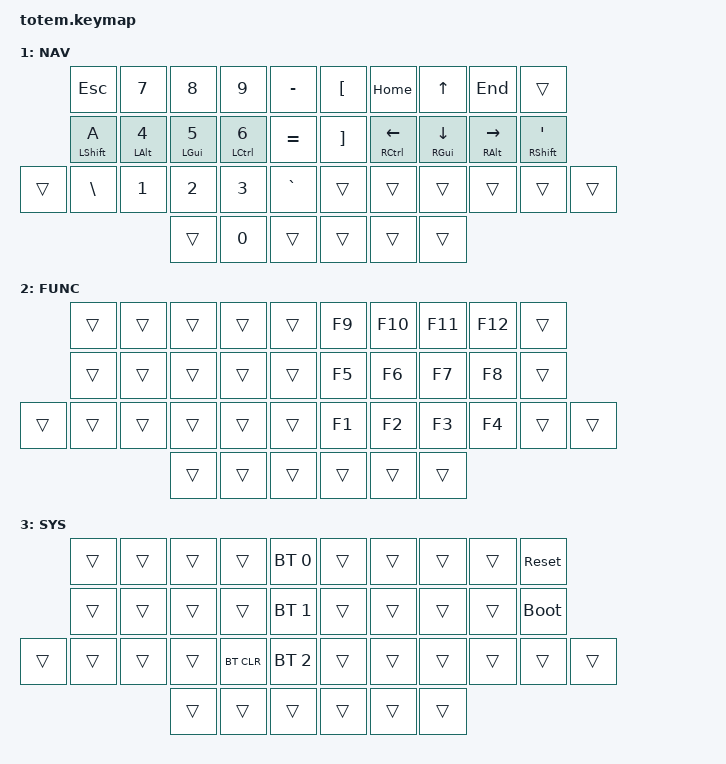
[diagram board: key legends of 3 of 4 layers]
//
//                                                        ▀▀▀▀▀     ▀▀▀▀▀          ▀▀█▀▀
//                                                        ▄▀▀▀▄  ▄  ▄▀▀▀▄  ▄  ▄▀▀▀▄  █  ▄▀▀▀▄
//                                                        █   █  █  █   █  █  █   █  █  █   █
//                                                         ▀▀▀   █   ▀▀▀   █   ▀▀▀   ▀   ▀▀▀
//                                                               █      ▄▄▄█▄▄▄    █   █  
//                                                               ▀      █  █  █     █▄█
//                                                             ▀▀▀▀▀    █  █  █      ▀
//                                                                      ▀  ▀  ▀
//
// ▄▄▄▄▄▄▄▄▄▄▄▄▄▄▄▄▄▄▄▄▄▄▄▄▄▄▄▄▄▄▄▄▄▄▄▄▄▄▄▄▄▄▄▄▄▄▄▄▄▄▄▄▄▄▄▄▄▄▄▄▄▄▄▄▄▄▄▄▄▄▄▄▄▄▄▄▄▄▄▄▄▄▄▄▄▄▄▄▄▄▄▄▄▄▄▄▄▄▄▄▄▄▄▄▄▄▄▄▄▄▄▄▄▄▄▄▄▄▄▄▄▄▄▄▄▄▄▄▄▄▄▄▄▄▄▄▄▄▄▄▄▄▄▄▄▄▄▄▄
       

#include <behaviors.dtsi>
#include <dt-bindings/zmk/keys.h>
#include <dt-bindings/zmk/bt.h>
#include <dt-bindings/zmk/outputs.h>

#define BASE 0
#define NAV  1
#define FUNC  2
#define SYS  3

// Home row mods macro
#define HRML(k1,k2,k3,k4) &ht LSHFT k1  &ht LALT k2  &ht LGUI k3  &ht LCTRL k4
#define HRMR(k1,k2,k3,k4) &ht LCTRL k1  &ht RGUI k2  &ht RALT k3  &ht RSHFT k4

/ {
    behaviors {
        td0: tap_dance_0 {
            compatible = "zmk,behavior-tap-dance";
            #binding-cells = <0>;
            tapping-term-ms = <200>;
            bindings = <&kp LG(C)>, <&kp LG(V)>, <&kp LG(X)>;
        };
        ht: hold_tap {
            compatible = "zmk,behavior-hold-tap";
            #binding-cells = <2>;
            flavor = "tap-preferred";
            tapping-term-ms = <200>;
            quick-tap-ms = <150>;
            require-prior-idle-ms = <100>;
            bindings = <&kp>, <&kp>;
        };
    };

     combos {
        compatible = "zmk,combos";
        combo_ralt {
            timeout-ms = <50>;
            key-positions = <16 17>;
            bindings = <&kp RALT>;
        };
        combo_caps {
            timeout-ms = <50>;
            key-positions = <12 13>;
            bindings = <&kp CAPS>;
        };
        combo_shift_q {
            timeout-ms = <35>;
            key-positions = <0 10>;
            bindings = <&kp LS(Q)>;
        };
        combo_shift_w {
            timeout-ms = <35>;
            key-positions = <1 10>;
            bindings = <&kp LS(W)>;
        };
        combo_shift_e {
            timeout-ms = <35>;
            key-positions = <2 10>;
            bindings = <&kp LS(E)>;
        };
        combo_shift_r {
            timeout-ms = <35>;
            key-positions = <3 10>;
            bindings = <&kp LS(R)>;
        };
        combo_shift_t {
            timeout-ms = <35>;
            key-positions = <4 10>;
            bindings = <&kp LS(T)>;
        };
        combo_shift_o {
            timeout-ms = <35>;
            key-positions = <8 19>;
            bindings = <&kp LS(O)>;
        };
        combo_shift_p {
            timeout-ms = <35>;
            key-positions = <9 19>;
            bindings = <&kp LS(P)>;
        };
    };

    conditional_layers {
        compatible = "zmk,conditional-layers";
        tri_layer {
            if-layers = <1 2>;
            then-layer = <3>;
        };
    };

    macros {
        langhold: langhold {
            compatible = "zmk,behavior-macro";
            label = "ZM_langhold";
            #binding-cells = <0>;
            bindings
            = <&macro_press &kp CAPS>
            , <&macro_pause_for_release>
            , <&macro_release &kp CAPS>
            ;
        };
    };

        keymap {
                compatible = "zmk,keymap";
// ▄▄▄▄▄▄▄▄▄▄▄▄▄▄▄▄▄▄▄▄▄▄▄▄▄▄▄▄▄▄▄▄▄▄▄▄▄▄▄▄▄▄▄▄▄▄▄▄▄▄▄▄▄▄▄▄▄▄▄▄▄▄▄▄▄▄▄▄▄▄▄▄▄▄▄▄▄▄▄▄▄▄▄▄▄▄▄▄▄▄▄▄▄▄▄▄▄▄▄▄▄▄▄▄▄▄▄▄▄▄▄▄▄▄▄▄▄▄▄▄▄▄▄▄▄▄▄▄▄▄▄▄▄▄▄▄▄▄▄▄▄▄▄▄▄▄▄▄▄

                base_layer {
// ┏━━━━━━━━━━━━━━━━━━━━━━━━━━━━━━━━━━━━━━━┓
label= "BASE"                              ;
// ┗━━━━━━━━━━━━━━━━━━━━━━━━━━━━━━━━━━━━━━━┛
//             ┏━━━━━━━━━━━┳━━━━━━━━━━━┳━━━━━━━━━━━┳━━━━━━━━━━━┳━━━━━━━━━━━┓   ┏━━━━━━━━━━━┳━━━━━━━━━━━┳━━━━━━━━━━━┳━━━━━━━━━━━┳━━━━━━━━━━━┓
//             ┃     Q     ┃     W     ┃     E     ┃     R     ┃     T     ┃   ┃     Y     ┃     U     ┃     I     ┃     O     ┃     P     ┃
//             ┣━━━━━━━━━━━╋━━━━━━━━━━━╋━━━━━━━━━━━╋━━━━━━━━━━━╋━━━━━━━━━━━┫   ┣━━━━━━━━━━━╋━━━━━━━━━━━╋━━━━━━━━━━━╋━━━━━━━━━━━╋━━━━━━━━━━━┫
//             ┃     A     ┃     S     ┃     D     ┃     F     ┃     G     ┃   ┃     H     ┃     J     ┃     K     ┃     L     ┃     ;     ┃
// ┏━━━━━━━━━━━╋━━━━━━━━━━━╋━━━━━━━━━━━╋━━━━━━━━━━━╋━━━━━━━━━━━╋━━━━━━━━━━━┫   ┣━━━━━━━━━━━╋━━━━━━━━━━━╋━━━━━━━━━━━╋━━━━━━━━━━━╋━━━━━━━━━━━╋━━━━━━━━━━━┓
// ┃    td0    ┃     Z     ┃     X     ┃     C     ┃     V     ┃     B     ┃   ┃     N     ┃     M     ┃     ,     ┃     .     ┃     /     ┃     \     ┃
// ┗━━━━━━━━━━━┻━━━━━━━━━━━┻━━━━━━━━━━━╋━━━━━━━━━━━╋━━━━━━━━━━━╋━━━━━━━━━━━┫   ┣━━━━━━━━━━━╋━━━━━━━━━━━╋━━━━━━━━━━━╋━━━━━━━━━━━┻━━━━━━━━━━━┻━━━━━━━━━━━┛
//                                     ┃    ESC    ┃    TAB    ┃    SPC    ┃   ┃   ENTER   ┃  BSPC     ┃   DEL     ┃
//                                     ┗━━━━━━━━━━━┻━━━━━━━━━━━┻━━━━━━━━━━━┛   ┗━━━━━━━━━━━┻━━━━━━━━━━━┻━━━━━━━━━━━┛
 bindings = <
// ╷           ╷           ╷           ╷           ╷           ╷           ╷   ╷           ╷           ╷           ╷           ╷           ╷           ╷

                &kp Q       &kp W       &kp E       &kp R       &kp T           &kp Y       &kp U       &kp I       &kp O       &kp P
                HRML(A,     S,          D,          F)          &kp G           &kp H       HRMR(J,     K,          L,          SEMI)
    &td0        &kp Z       &kp X       &kp C       &kp V       &kp B           &kp N       &kp M       &kp COMMA   &kp DOT     &kp FSLH    &langhold
                                        &kp ESC     &kp TAB     &lt 1 SPACE     &lt 1 ENTER &lt 2 BSPC  &kp DEL
                        >;
                };

// ▄▄▄▄▄▄▄▄▄▄▄▄▄▄▄▄▄▄▄▄▄▄▄▄▄▄▄▄▄▄▄▄▄▄▄▄▄▄▄▄▄▄▄▄▄▄▄▄▄▄▄▄▄▄▄▄▄▄▄▄▄▄▄▄▄▄▄▄▄▄▄▄▄▄▄▄▄▄▄▄▄▄▄▄▄▄▄▄▄▄▄▄▄▄▄▄▄▄▄▄▄▄▄▄▄▄▄▄▄▄▄▄▄▄▄▄▄▄▄▄▄▄▄▄▄▄▄▄▄▄▄▄▄▄▄▄▄▄▄▄▄▄▄▄▄▄▄▄▄


                nav_layer {
// ┏━━━━━━━━━━━━━━━━━━━━━━━━━━━━━━━━━━━━━━━┓
label= "NAV"                              ;
// ┗━━━━━━━━━━━━━━━━━━━━━━━━━━━━━━━━━━━━━━━┛
//             ┏━━━━━━━━━━━┳━━━━━━━━━━━┳━━━━━━━━━━━┳━━━━━━━━━━━┳━━━━━━━━━━━┓   ┏━━━━━━━━━━━┳━━━━━━━━━━━┳━━━━━━━━━━━┳━━━━━━━━━━━┳━━━━━━━━━━━┓
//             ┃    ESC    ┃     7     ┃     8     ┃     9     ┃     -     ┃   ┃     [     ┃   HOME    ┃    UP     ┃    END    ┃           ┃
//             ┣━━━━━━━━━━━╋━━━━━━━━━━━╋━━━━━━━━━━━╋━━━━━━━━━━━╋━━━━━━━━━━━┫   ┣━━━━━━━━━━━╋━━━━━━━━━━━╋━━━━━━━━━━━╋━━━━━━━━━━━╋━━━━━━━━━━━┫
//             ┃           ┃     4     ┃     5     ┃     6     ┃     =     ┃   ┃     ]     ┃   LEFT    ┃   DOWN    ┃   RIGHT   ┃     '     ┃
// ┏━━━━━━━━━━━╋━━━━━━━━━━━╋━━━━━━━━━━━╋━━━━━━━━━━━╋━━━━━━━━━━━╋━━━━━━━━━━━┫   ┣━━━━━━━━━━━╋━━━━━━━━━━━╋━━━━━━━━━━━╋━━━━━━━━━━━╋━━━━━━━━━━━╋━━━━━━━━━━━┓
// ┃           ┃    BSLH   ┃     1     ┃     2     ┃     3     ┃     ~     ┃   ┃           ┃           ┃           ┃           ┃           ┃           ┃
// ┗━━━━━━━━━━━┻━━━━━━━━━━━┻━━━━━━━━━━━╋━━━━━━━━━━━╋━━━━━━━━━━━╋━━━━━━━━━━━┫   ┣━━━━━━━━━━━╋━━━━━━━━━━━╋━━━━━━━━━━━╋━━━━━━━━━━━┻━━━━━━━━━━━┻━━━━━━━━━━━┛
//                                     ┃           ┃     0     ┃           ┃   ┃           ┃           ┃           ┃
//                                     ┗━━━━━━━━━━━┻━━━━━━━━━━━┻━━━━━━━━━━━┛   ┗━━━━━━━━━━━┻━━━━━━━━━━━┻━━━━━━━━━━━┛
 bindings = <
// ╷           ╷           ╷           ╷           ╷           ╷           ╷   ╷           ╷           ╷           ╷           ╷           ╷           ╷

                &kp ESC     &kp N7      &kp N8      &kp N9       &kp MINUS       &kp LBKT  &kp HOME       &kp UP        &kp END        &trans
                &mt LSHFT A &mt LALT N4 &mt LGUI N5 &mt LCTRL N6 &kp EQUAL       &kp RBKT  &mt RCTRL LEFT &mt RGUI DOWN &mt RALT RIGHT &mt RSHFT SQT
    &trans      &kp BSLH    &kp N1      &kp N2      &kp N3       &kp GRAVE       &trans    &trans         &trans        &trans         &trans       &trans
                                        &trans      &kp N0       &trans          &trans    &trans         &trans      
                        >;
                };

// ▄▄▄▄▄▄▄▄▄▄▄▄▄▄▄▄▄▄▄▄▄▄▄▄▄▄▄▄▄▄▄▄▄▄▄▄▄▄▄▄▄▄▄▄▄▄▄▄▄▄▄▄▄▄▄▄▄▄▄▄▄▄▄▄▄▄▄▄▄▄▄▄▄▄▄▄▄▄▄▄▄▄▄▄▄▄▄▄▄▄▄▄▄▄▄▄▄▄▄▄▄▄▄▄▄▄▄▄▄▄▄▄▄▄▄▄▄▄▄▄▄▄▄▄▄▄▄▄▄▄▄▄▄▄▄▄▄▄▄▄▄▄▄▄▄▄▄▄▄


                func_layer {
// ┏━━━━━━━━━━━━━━━━━━━━━━━━━━━━━━━━━━━━━━━┓
label= "FUNC"                               ;
// ┗━━━━━━━━━━━━━━━━━━━━━━━━━━━━━━━━━━━━━━━┛
//             ┏━━━━━━━━━━━┳━━━━━━━━━━━┳━━━━━━━━━━━┳━━━━━━━━━━━┳━━━━━━━━━━━┓   ┏━━━━━━━━━━━┳━━━━━━━━━━━┳━━━━━━━━━━━┳━━━━━━━━━━━┳━━━━━━━━━━━┓
//             ┃           ┃           ┃           ┃           ┃           ┃   ┃   F9      ┃   F10     ┃   F11     ┃   F12     ┃           ┃
//             ┣━━━━━━━━━━━╋━━━━━━━━━━━╋━━━━━━━━━━━╋━━━━━━━━━━━╋━━━━━━━━━━━┫   ┣━━━━━━━━━━━╋━━━━━━━━━━━╋━━━━━━━━━━━╋━━━━━━━━━━━╋━━━━━━━━━━━┫
//             ┃           ┃           ┃           ┃           ┃           ┃   ┃   F5      ┃   F6      ┃   F7      ┃   F8      ┃           ┃
// ┏━━━━━━━━━━━╋━━━━━━━━━━━╋━━━━━━━━━━━╋━━━━━━━━━━━╋━━━━━━━━━━━╋━━━━━━━━━━━┫   ┣━━━━━━━━━━━╋━━━━━━━━━━━╋━━━━━━━━━━━╋━━━━━━━━━━━╋━━━━━━━━━━━╋━━━━━━━━━━━┓
// ┃           ┃           ┃           ┃           ┃           ┃           ┃   ┃   F1      ┃   F2      ┃   F3      ┃   F4      ┃           ┃           ┃
// ┗━━━━━━━━━━━┻━━━━━━━━━━━┻━━━━━━━━━━━╋━━━━━━━━━━━╋━━━━━━━━━━━╋━━━━━━━━━━━┫   ┣━━━━━━━━━━━╋━━━━━━━━━━━╋━━━━━━━━━━━╋━━━━━━━━━━━┻━━━━━━━━━━━┻━━━━━━━━━━━┛
//                                     ┃           ┃           ┃           ┃   ┃           ┃           ┃           ┃
//                                     ┗━━━━━━━━━━━┻━━━━━━━━━━━┻━━━━━━━━━━━┛   ┗━━━━━━━━━━━┻━━━━━━━━━━━┻━━━━━━━━━━━┛
 bindings = <
// ╷           ╷           ╷           ╷           ╷           ╷           ╷   ╷           ╷           ╷           ╷           ╷           ╷           ╷

                &trans     &trans       &trans       &trans      &trans         &kp F9      &kp F10     &kp F11      &kp F12     &trans       
                &trans     &trans       &trans       &trans      &trans         &kp F5      &kp F6      &kp F7       &kp F8      &trans 
    &trans      &trans     &trans       &trans       &trans      &trans         &kp F1      &kp F2      &kp F3       &kp F4      &trans      &trans         
                                        &trans       &trans      &trans         &trans      &trans      &trans      
                        >;
                };

// ▄▄▄▄▄▄▄▄▄▄▄▄▄▄▄▄▄▄▄▄▄▄▄▄▄▄▄▄▄▄▄▄▄▄▄▄▄▄▄▄▄▄▄▄▄▄▄▄▄▄▄▄▄▄▄▄▄▄▄▄▄▄▄▄▄▄▄▄▄▄▄▄▄▄▄▄▄▄▄▄▄▄▄▄▄▄▄▄▄▄▄▄▄▄▄▄▄▄▄▄▄▄▄▄▄▄▄▄▄▄▄▄▄▄▄▄▄▄▄▄▄▄▄▄▄▄▄▄▄▄▄▄▄▄▄▄▄▄▄▄▄▄▄▄▄▄▄▄▄


                sys_layer {
// ┏━━━━━━━━━━━━━━━━━━━━━━━━━━━━━━━━━━━━━━━┓
label= "SYS"                               ;
// ┗━━━━━━━━━━━━━━━━━━━━━━━━━━━━━━━━━━━━━━━┛
//             ┏━━━━━━━━━━━┳━━━━━━━━━━━┳━━━━━━━━━━━┳━━━━━━━━━━━┳━━━━━━━━━━━┓   ┏━━━━━━━━━━━┳━━━━━━━━━━━┳━━━━━━━━━━━┳━━━━━━━━━━━┳━━━━━━━━━━━┓
//             ┃           ┃           ┃           ┃           ┃ PROF0     ┃   ┃           ┃           ┃           ┃           ┃   RESET   ┃
//             ┣━━━━━━━━━━━╋━━━━━━━━━━━╋━━━━━━━━━━━╋━━━━━━━━━━━╋━━━━━━━━━━━┫   ┣━━━━━━━━━━━╋━━━━━━━━━━━╋━━━━━━━━━━━╋━━━━━━━━━━━╋━━━━━━━━━━━┫
//             ┃           ┃           ┃           ┃           ┃ PROF1     ┃   ┃           ┃           ┃           ┃           ┃  BOOTLOAD ┃
// ┏━━━━━━━━━━━╋━━━━━━━━━━━╋━━━━━━━━━━━╋━━━━━━━━━━━╋━━━━━━━━━━━╋━━━━━━━━━━━┫   ┣━━━━━━━━━━━╋━━━━━━━━━━━╋━━━━━━━━━━━╋━━━━━━━━━━━╋━━━━━━━━━━━╋━━━━━━━━━━━┓
// ┃           ┃           ┃           ┃           ┃  CLEAR    ┃ PROF2     ┃   ┃           ┃           ┃           ┃           ┃           ┃           ┃
// ┗━━━━━━━━━━━┻━━━━━━━━━━━┻━━━━━━━━━━━╋━━━━━━━━━━━╋━━━━━━━━━━━╋━━━━━━━━━━━┫   ┣━━━━━━━━━━━╋━━━━━━━━━━━╋━━━━━━━━━━━╋━━━━━━━━━━━┻━━━━━━━━━━━┻━━━━━━━━━━━┛
//                                     ┃           ┃           ┃           ┃   ┃           ┃           ┃           ┃
//                                     ┗━━━━━━━━━━━┻━━━━━━━━━━━┻━━━━━━━━━━━┛   ┗━━━━━━━━━━━┻━━━━━━━━━━━┻━━━━━━━━━━━┛
 bindings = <
// ╷           ╷           ╷           ╷           ╷           ╷           ╷   ╷           ╷           ╷           ╷           ╷           ╷           ╷

                &trans     &trans       &trans       &trans      &bt BT_SEL 0   &trans      &trans      &trans       &trans      &sys_reset       
                &trans     &trans       &trans       &trans      &bt BT_SEL 1   &trans      &trans      &trans       &trans      &bootloader 
    &trans      &trans     &trans       &trans       &bt BT_CLR  &bt BT_SEL 2   &trans      &trans      &trans       &trans      &trans     &trans         
                                        &trans       &trans      &trans         &trans      &trans      &trans      
                        >;
                };

// ▄▄▄▄▄▄▄▄▄▄▄▄▄▄▄▄▄▄▄▄▄▄▄▄▄▄▄▄▄▄▄▄▄▄▄▄▄▄▄▄▄▄▄▄▄▄▄▄▄▄▄▄▄▄▄▄▄▄▄▄▄▄▄▄▄▄▄▄▄▄▄▄▄▄▄▄▄▄▄▄▄▄▄▄▄▄▄▄▄▄▄▄▄▄▄▄▄▄▄▄▄▄▄▄▄▄▄▄▄▄▄▄▄▄▄▄▄▄▄▄▄▄▄▄▄▄▄▄▄▄▄▄▄▄▄▄▄▄▄▄▄▄▄▄▄▄▄▄▄

         };
};
